# HC32F115 register map
File version: 1.0
CPU: CM0+ r0p1, little endian, no MPU, no FPU, 2 interrupt priority bits
Registers are 32-bit, read-write, reset 0x0 unless marked. A register's access mark holds for its fields unless they carry their own. Offsets are from the block's base; [hi:lo] are bit positions; {n}, {i} and the like mark numbered series; 'fields as' and 'values as' point back to an identical list.

## GPIO
Base 0x40013800
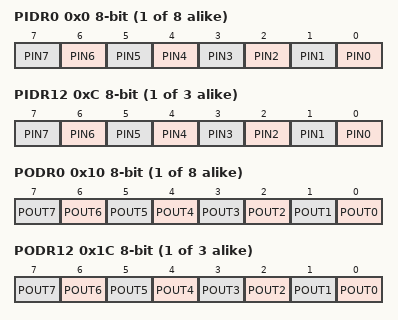
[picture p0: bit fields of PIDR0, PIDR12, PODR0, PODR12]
{0x0+i} PIDR{i} 8-bit ro (i=0..7)
  [n] PIN{n} (n=0..7)
{0x0+i} PIDR{i} 8-bit ro (i=12..14)
  [n] PIN{n} (n=0..7)
{0x10+i} PODR{i} 8-bit (i=0..7)
  [n] POUT{n} (n=0..7)
{0x10+i} PODR{i} 8-bit (i=12..14)
  [n] POUT{n} (n=0..7)
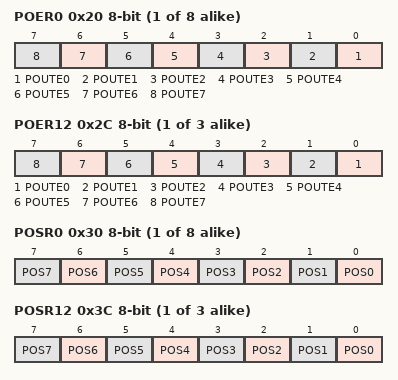
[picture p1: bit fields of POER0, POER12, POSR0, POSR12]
{0x20+i} POER{i} 8-bit (i=0..7)
  [n] POUTE{n} (n=0..7)
{0x20+i} POER{i} 8-bit (i=12..14)
  [n] POUTE{n} (n=0..7)
{0x30+i} POSR{i} 8-bit wo (i=0..7)
  [n] POS{n} (n=0..7)
{0x30+i} POSR{i} 8-bit wo (i=12..14)
  [n] POS{n} (n=0..7)
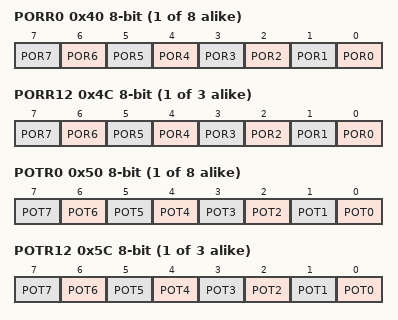
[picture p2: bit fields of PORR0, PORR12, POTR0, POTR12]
{0x40+i} PORR{i} 8-bit wo (i=0..7)
  [n] POR{n} (n=0..7)
{0x40+i} PORR{i} 8-bit wo (i=12..14)
  [n] POR{n} (n=0..7)
{0x50+i} POTR{i} 8-bit wo (i=0..7)
  [n] POT{n} (n=0..7)
{0x50+i} POTR{i} 8-bit wo (i=12..14)
  [n] POT{n} (n=0..7)
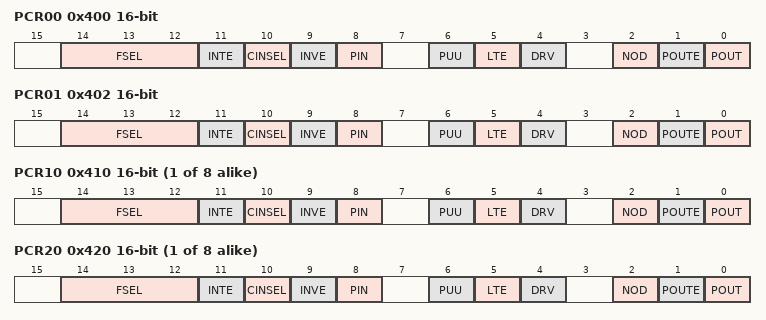
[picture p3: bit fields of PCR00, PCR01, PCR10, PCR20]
0x400 PCR00 16-bit
  [14:12] FSEL, [11] INTE, [10] CINSEL, [9] INVE, [8] PIN ro, [6] PUU, [5] LTE, [4] DRV, [2] NOD, [1] POUTE, [0] POUT
0x402 PCR01 16-bit
  fields as PCR00
{0x3FC+2i} PCR{i} 16-bit (i=10..17)
  fields as PCR00
{0x3F8+2i} PCR{i} 16-bit (i=20..27)
  fields as PCR00
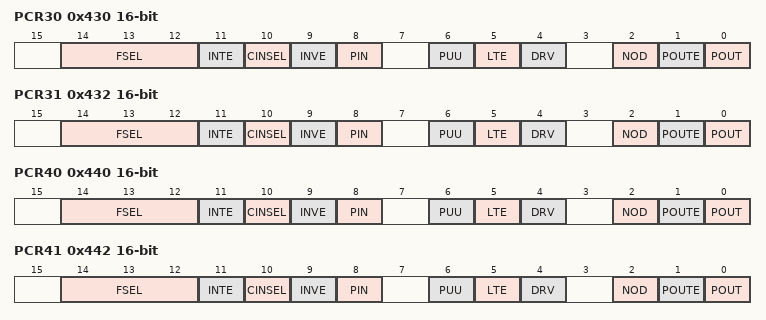
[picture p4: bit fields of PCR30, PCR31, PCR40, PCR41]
0x430 PCR30 16-bit
  fields as PCR00
0x432 PCR31 16-bit
  fields as PCR00
0x440 PCR40 16-bit
  fields as PCR00
0x442 PCR41 16-bit
  fields as PCR00
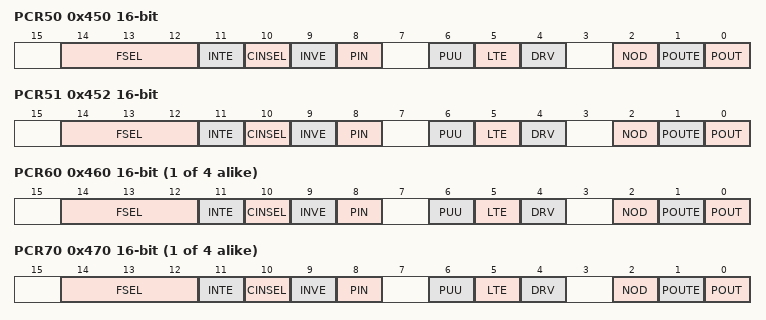
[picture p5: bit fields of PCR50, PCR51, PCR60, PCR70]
0x450 PCR50 16-bit
  fields as PCR00
0x452 PCR51 16-bit
  fields as PCR00
{0x3E8+2i} PCR{i} 16-bit (i=60..63)
  fields as PCR00
{0x3E4+2i} PCR{i} 16-bit (i=70..73)
  fields as PCR00
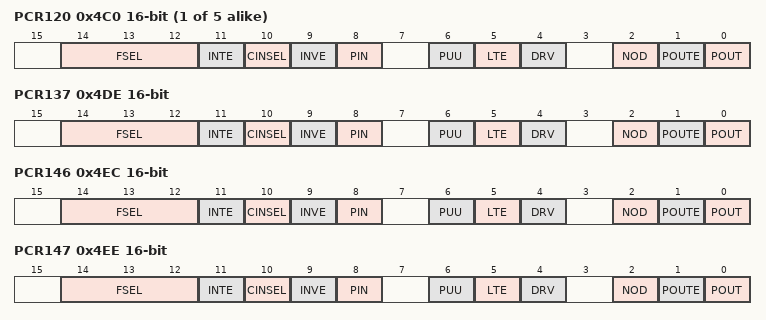
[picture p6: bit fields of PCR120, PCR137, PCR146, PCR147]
{0x3D0+2i} PCR{i} 16-bit (i=120..124)
  fields as PCR00
0x4DE PCR137 16-bit
  fields as PCR00
0x4EC PCR146 16-bit
  fields as PCR00
0x4EE PCR147 16-bit
  fields as PCR00
0x500 PSPCR 16-bit reset 0x3
  [1:0] SPFE
0x504 PCCR 16-bit reset 0x4000
  [15:14] RDWT
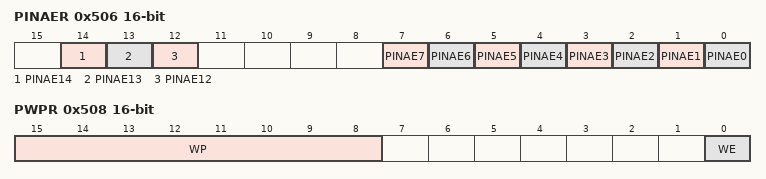
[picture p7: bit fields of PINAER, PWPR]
0x506 PINAER 16-bit
  [14] PINAE14, [13] PINAE13, [12] PINAE12, [n] PINAE{n} (n=0..7)
0x508 PWPR 16-bit
  [15:8] WP wo, [0] WE

## I2C
Base 0x40004800
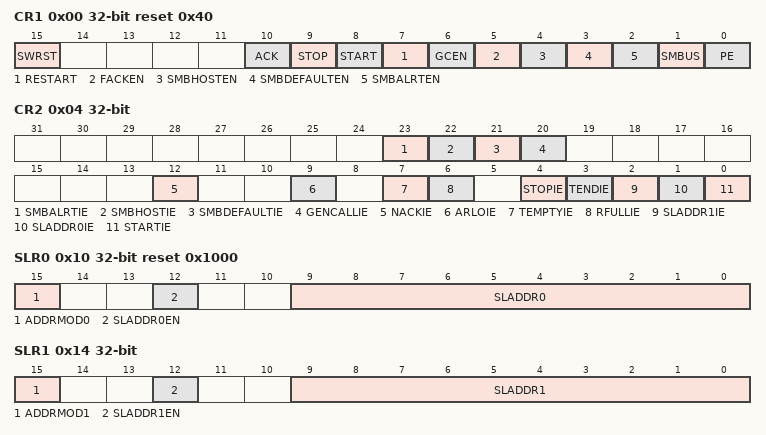
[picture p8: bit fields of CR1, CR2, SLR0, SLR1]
0x00 CR1 reset 0x40
  [15] SWRST, [10] ACK, [9] STOP, [8] START, [7] RESTART, [6] GCEN, [5] FACKEN, [4] SMBHOSTEN, [3] SMBDEFAULTEN, [2] SMBALRTEN, [1] SMBUS, [0] PE
0x04 CR2
  [23] SMBALRTIE, [22] SMBHOSTIE, [21] SMBDEFAULTIE, [20] GENCALLIE, [12] NACKIE, [9] ARLOIE, [7] TEMPTYIE, [6] RFULLIE, [4] STOPIE, [3] TENDIE, [2] SLADDR1IE, [1] SLADDR0IE, [0] STARTIE
0x0C CR4 reset 0x707
  [10] BUSWAIT
0x10 SLR0 reset 0x1000
  [15] ADDRMOD0, [12] SLADDR0EN, [9:0] SLADDR0
0x14 SLR1
  [15] ADDRMOD1, [12] SLADDR1EN, [9:0] SLADDR1
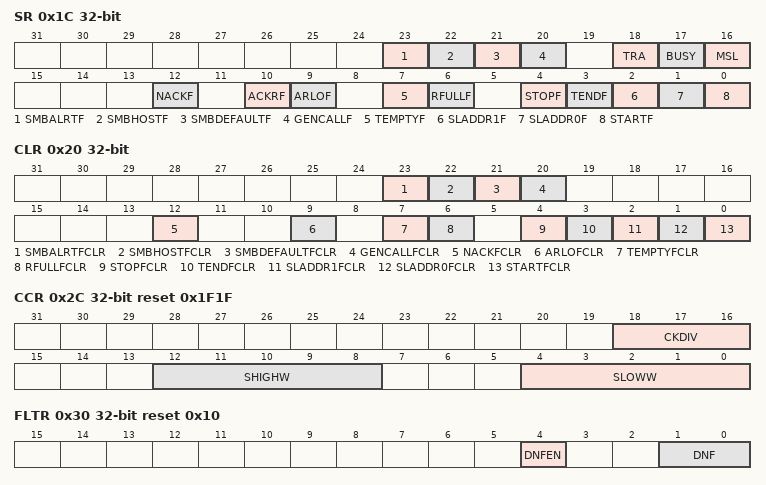
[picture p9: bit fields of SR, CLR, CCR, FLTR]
0x1C SR
  [23] SMBALRTF ro, [22] SMBHOSTF ro, [21] SMBDEFAULTF ro, [20] GENCALLF ro, [18] TRA, [17] BUSY ro, [16] MSL, [12] NACKF ro, [10] ACKRF ro, [9] ARLOF ro, [7] TEMPTYF ro, [6] RFULLF ro, [4] STOPF ro, [3] TENDF ro, [2] SLADDR1F ro, [1] SLADDR0F ro, [0] STARTF ro
0x20 CLR wo
  [23] SMBALRTFCLR, [22] SMBHOSTFCLR, [21] SMBDEFAULTFCLR, [20] GENCALLFCLR, [12] NACKFCLR, [9] ARLOFCLR, [7] TEMPTYFCLR, [6] RFULLFCLR, [4] STOPFCLR, [3] TENDFCLR, [2] SLADDR1FCLR, [1] SLADDR0FCLR, [0] STARTFCLR
0x24 DTR 8-bit reset 0xFF
  [7:0] DT
0x28 DRR 8-bit
  [7:0] DR
0x2C CCR reset 0x1F1F
  [18:16] CKDIV, [12:8] SHIGHW, [4:0] SLOWW
0x30 FLTR reset 0x10
  [4] DNFEN, [1:0] DNF

## ICG
Base 0x000000C0
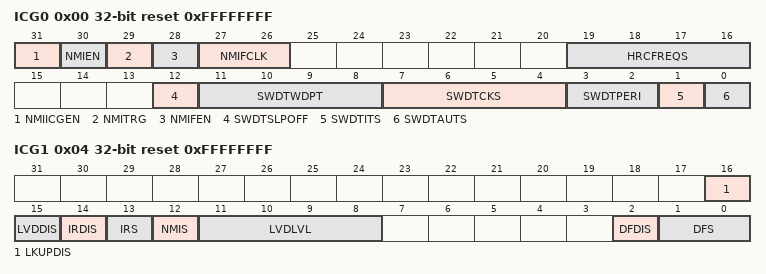
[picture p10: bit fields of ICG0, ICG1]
0x00 ICG0 ro reset 0xFFFFFFFF
  [31] NMIICGEN, [30] NMIEN, [29] NMITRG, [28] NMIFEN, [27:26] NMIFCLK, [19:16] HRCFREQS, [12] SWDTSLPOFF, [11:8] SWDTWDPT, [7:4] SWDTCKS, [3:2] SWDTPERI, [1] SWDTITS, [0] SWDTAUTS
0x04 ICG1 ro reset 0xFFFFFFFF
  [16] LKUPDIS, [15] LVDDIS, [14] IRDIS, [13] IRS, [12] NMIS, [11:8] LVDLVL, [2] DFDIS, [1:0] DFS
{0x0+4i} ICG{i} ro reset 0xFFFFFFFF (reset mask 0x0) (i=2..6)

## INTC
Base 0x40011000
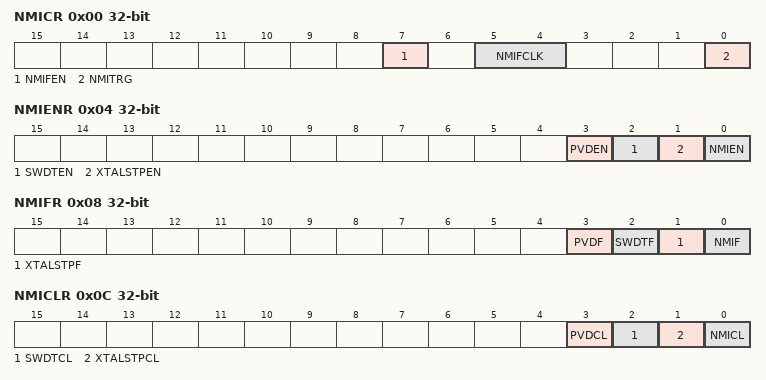
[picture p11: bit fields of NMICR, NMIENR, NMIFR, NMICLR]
0x00 NMICR
  [7] NMIFEN, [5:4] NMIFCLK, [0] NMITRG
0x04 NMIENR
  [3] PVDEN, [2] SWDTEN, [1] XTALSTPEN, [0] NMIEN
0x08 NMIFR ro
  [3] PVDF, [2] SWDTF, [1] XTALSTPF, [0] NMIF
0x0C NMICLR
  [3] PVDCL, [2] SWDTCL, [1] XTALSTPCL, [0] NMICL
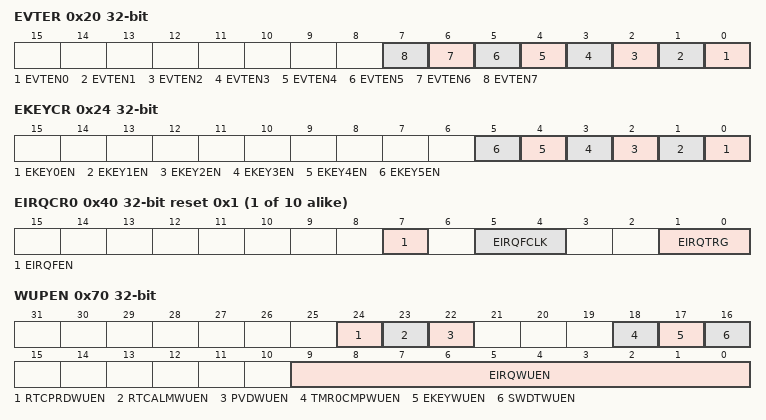
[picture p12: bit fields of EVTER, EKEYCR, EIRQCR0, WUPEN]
0x20 EVTER
  [n] EVTEN{n} (n=0..7)
0x24 EKEYCR
  [n] EKEY{n}EN (n=0..5)
0x3C FPRCR
  [7:0] FPRC
{0x40+4i} EIRQCR{i} reset 0x1 (i=0..9)
  [7] EIRQFEN, [5:4] EIRQFCLK, [1:0] EIRQTRG
0x70 WUPEN
  [24] RTCPRDWUEN, [23] RTCALMWUEN, [22] PVDWUEN, [18] TMR0CMPWUEN, [17] EKEYWUEN, [16] SWDTWUEN, [9:0] EIRQWUEN
0x74 EIRQFR
  [9:0] EIRQF
0x78 EIRQCLR
  [9:0] EIRQCL
{0x80+4i} ISELAR{i} (i=8..23)
  [3:0] ISEL
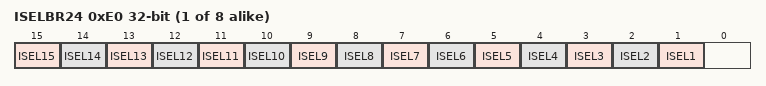
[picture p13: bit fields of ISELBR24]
{0x80+4i} ISELBR{i} (i=24..31)
  [n] ISEL{n} (n=1..15)
